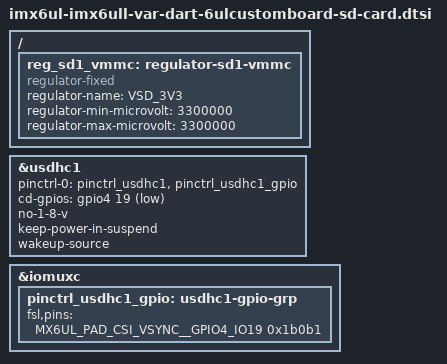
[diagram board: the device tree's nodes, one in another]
// SPDX-License-Identifier: GPL-2.0+
/*
 * Copyright (C) 2026 Variscite Ltd. - https://www.variscite.com
 */

/ {
	reg_sd1_vmmc: regulator-sd1-vmmc {
		compatible = "regulator-fixed";
		regulator-name = "VSD_3V3";
		regulator-min-microvolt = <3300000>;
		regulator-max-microvolt = <3300000>;
	};
};

&usdhc1 {
	pinctrl-names = "default";
	pinctrl-0 = <&pinctrl_usdhc1>, <&pinctrl_usdhc1_gpio>;
	cd-gpios = <&gpio4 19 GPIO_ACTIVE_LOW>;
	no-1-8-v;
	keep-power-in-suspend;
	wakeup-source;
	status = "okay";
};

&iomuxc {
	pinctrl_usdhc1_gpio: usdhc1-gpio-grp {
		fsl,pins = <
			MX6UL_PAD_CSI_VSYNC__GPIO4_IO19		0x1b0b1
		>;
	};
};
